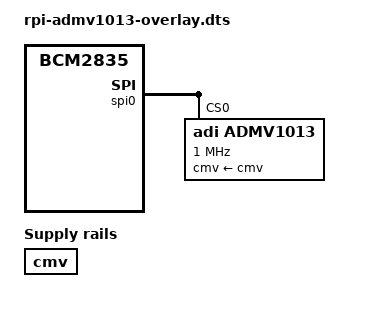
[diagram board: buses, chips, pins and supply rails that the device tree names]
/dts-v1/;
/plugin/;

/ {
	compatible = "brcm,bcm2835";



	fragment@0 {
		target = <&spidev0>;

		__overlay__ {
			status = "disabled";
		};
	};

	fragment@1 {
		target-path = "/";
		__overlay__ {
			clocks {
				admv1013_lo: clock@0 {
					compatible = "fixed-clock";

					clock-frequency = <100000000>;
					clock-output-names = "lo_in";
					#clock-cells = <1>;
				};
			};
		};
	};

	fragment@2 {
		target-path = "/";
		__overlay__ {
			cmv: fixedregulator@0 {
				compatible = "regulator-fixed";
				regulator-name = "cmv";
				regulator-min-microvolt = <0>;
				regulator-max-microvolt = <0>;
				regulator-boot-on;
			};
		};
	};

	fragment@3 {
		target = <&spi0>;

		__overlay__{
			#address-cells = <1>;
			#size-cells = <0>;
			status = "okay";

			admv1013@0{
				compatible = "adi,admv1013";
				reg = <0>;
				spi-max-frequency = <1000000>;
				clocks = <&admv1013_lo 3>;
				clock-names = "lo_in";
				cmv-supply = <&cmv>;
				adi,quad-se-mode = <0>;
			};
		};
	};
}; 
